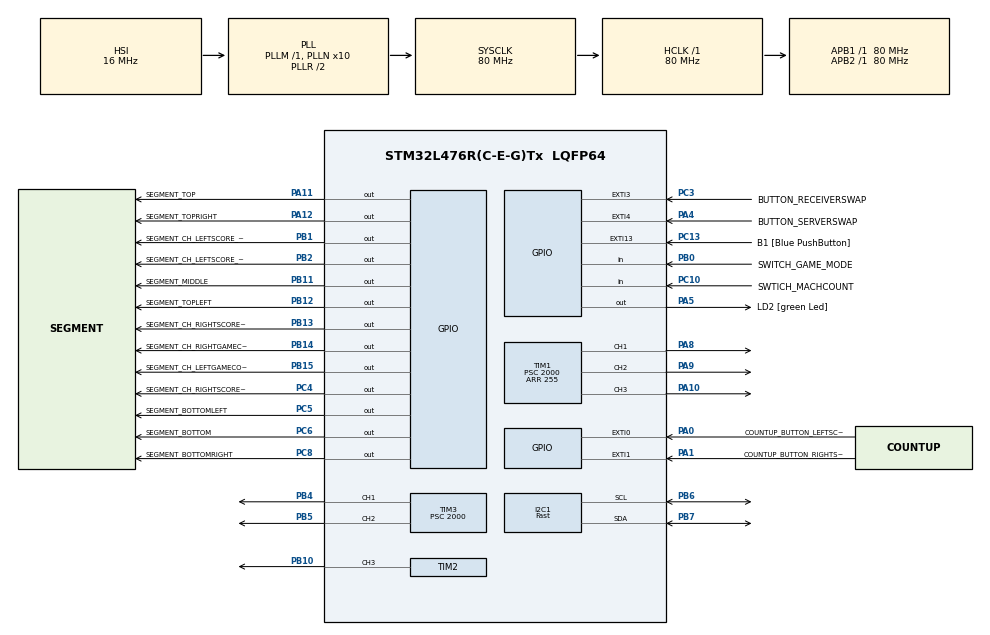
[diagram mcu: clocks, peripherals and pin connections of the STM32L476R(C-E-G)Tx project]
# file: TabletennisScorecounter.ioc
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I2C1.I2C_Speed_Mode=I2C_Fast
I2C1.Timing=0x00702991
Mcu.Family=STM32L4
Mcu.Name=STM32L476R(C-E-G)Tx
Mcu.Package=LQFP64
NVIC.EXTI0_IRQn=true\:0\:0\:false\:false\:true\:true
NVIC.EXTI15_10_IRQn=true\:0\:0\:false\:false\:true\:true
NVIC.EXTI1_IRQn=true\:0\:0\:false\:false\:true\:true
NVIC.EXTI3_IRQn=true\:0\:0\:false\:false\:true\:true
NVIC.EXTI4_IRQn=true\:0\:0\:false\:false\:true\:true
NVIC.PriorityGroup=NVIC_PRIORITYGROUP_4
NVIC.TIM2_IRQn=true\:0\:0\:false\:false\:true\:true
NVIC.TIM3_IRQn=true\:0\:0\:false\:false\:true\:true
NVIC.TIM4_IRQn=true\:0\:0\:false\:false\:true\:true
NVIC.TIM5_IRQn=true\:0\:0\:false\:false\:true\:true
PA0.GPIO_Label=COUNTUP_BUTTON_LEFTSCORE
PA0.GPIO_ModeDefaultEXTI=GPIO_MODE_IT_RISING
PA0.GPIO_PuPd=GPIO_NOPULL
PA0.Signal=GPXTI0
PA1.GPIO_Label=COUNTUP_BUTTON_RIGHTSCORE
PA1.GPIO_ModeDefaultEXTI=GPIO_MODE_IT_RISING
PA1.GPIO_PuPd=GPIO_NOPULL
PA1.Signal=GPXTI1
PA10.Signal=S_TIM1_CH3
PA11.GPIO_Label=SEGMENT_TOP
PA11.Signal=GPIO_Output
PA12.GPIO_Label=SEGMENT_TOPRIGHT
PA12.Signal=GPIO_Output
PA13\ (JTMS-SWDIO).GPIO_Label=TMS
PA13\ (JTMS-SWDIO).Signal=SYS_JTMS-SWDIO
PA14\ (JTCK-SWCLK).GPIO_Label=TCK
PA14\ (JTCK-SWCLK).Signal=SYS_JTCK-SWCLK
PA4.GPIO_Label=BUTTON_SERVERSWAP
PA4.GPIO_PuPd=GPIO_PULLUP
PA4.Signal=GPXTI4
PA5.GPIO_Label=LD2 [green Led]
PA5.GPIO_ModeDefaultOutputPP=GPIO_MODE_OUTPUT_PP
PA5.GPIO_PuPd=GPIO_NOPULL
PA5.GPIO_Speed=GPIO_SPEED_FREQ_LOW
PA5.Signal=GPIO_Output
PA8.Signal=S_TIM1_CH1
PA9.Signal=S_TIM1_CH2
PB0.GPIO_Label=SWITCH_GAME_MODE
PB0.GPIO_PuPd=GPIO_PULLUP
PB0.Signal=GPIO_Input
PB1.GPIO_Label=SEGMENT_CH_LEFTSCORE_UPPER
PB1.Signal=GPIO_Output
PB10.Signal=S_TIM2_CH3
PB11.GPIO_Label=SEGMENT_MIDDLE
PB11.Signal=GPIO_Output
PB12.GPIO_Label=SEGMENT_TOPLEFT
PB12.Signal=GPIO_Output
PB13.GPIO_Label=SEGMENT_CH_RIGHTSCORE_LOWER
PB13.Signal=GPIO_Output
PB14.GPIO_Label=SEGMENT_CH_RIGHTGAMECOUNT
PB14.Signal=GPIO_Output
PB15.GPIO_Label=SEGMENT_CH_LEFTGAMECOUNT
PB15.Signal=GPIO_Output
PB2.GPIO_Label=SEGMENT_CH_LEFTSCORE_LOWER
PB2.Signal=GPIO_Output
PB3\ (JTDO-TRACESWO).GPIO_Label=SWO
PB3\ (JTDO-TRACESWO).Signal=SYS_JTDO-SWO
PB4\ (NJTRST).Signal=S_TIM3_CH1
PB5.Signal=S_TIM3_CH2
PB6.Mode=I2C
PB6.Signal=I2C1_SCL
PB7.Mode=I2C
PB7.Signal=I2C1_SDA
PC10.GPIO_Label=SWTICH_MACHCOUNT
PC10.Signal=GPIO_Input
PC13.GPIO_Label=B1 [Blue PushButton]
PC13.GPIO_ModeDefaultEXTI=GPIO_MODE_IT_RISING
PC13.GPIO_PuPd=GPIO_PULLDOWN
PC13.Signal=GPXTI13
PC14-OSC32_IN\ (PC14).Signal=RCC_OSC32_IN
PC15-OSC32_OUT\ (PC15).Signal=RCC_OSC32_OUT
PC3.GPIO_Label=BUTTON_RECEIVERSWAP
PC3.GPIO_PuPd=GPIO_PULLUP
PC3.Signal=GPXTI3
PC4.GPIO_Label=SEGMENT_CH_RIGHTSCORE_UPPER
PC4.Signal=GPIO_Output
PC5.GPIO_Label=SEGMENT_BOTTOMLEFT
PC5.Signal=GPIO_Output
PC6.GPIO_Label=SEGMENT_BOTTOM
PC6.Signal=GPIO_Output
PC8.GPIO_Label=SEGMENT_BOTTOMRIGHT
PC8.Signal=GPIO_Output
PH0-OSC_IN\ (PH0).Signal=RCC_OSC_IN
PH1-OSC_OUT\ (PH1).Signal=RCC_OSC_OUT
ProjectManager.HeapSize=0x200
ProjectManager.StackSize=0x400
ProjectManager.TargetToolchain=Makefile
RCC.ADCFreq_Value=64000000
RCC.AHBFreq_Value=80000000
RCC.APB1Freq_Value=80000000
RCC.APB1TimFreq_Value=80000000
RCC.APB2Freq_Value=80000000
RCC.APB2TimFreq_Value=80000000
RCC.CortexFreq_Value=80000000
RCC.HCLKFreq_Value=80000000
RCC.HSE_VALUE=8000000
RCC.HSI_VALUE=16000000
RCC.LSE_VALUE=32768
RCC.MSI_VALUE=4000000
RCC.PLLN=10
RCC.PLLSourceVirtual=RCC_PLLSOURCE_HSI
RCC.PREFETCH_ENABLE=1
RCC.SYSCLKFreq_VALUE=80000000
RCC.SYSCLKSource=RCC_SYSCLKSOURCE_PLLCLK
RCC.USBFreq_Value=64000000
RCC.VCOOutputFreq_Value=160000000
SH.S_TIM1_CH1.0=TIM1_CH1,PWM Generation1 CH1
SH.S_TIM1_CH2.0=TIM1_CH2,PWM Generation2 CH2
SH.S_TIM1_CH3.0=TIM1_CH3,PWM Generation3 CH3
SH.S_TIM2_CH3.0=TIM2_CH3,PWM Generation3 CH3
SH.S_TIM3_CH1.0=TIM3_CH1,PWM Generation1 CH1
SH.S_TIM3_CH2.0=TIM3_CH2,PWM Generation2 CH2
TIM1.Channel-PWM\ Generation1\ CH1=TIM_CHANNEL_1
TIM1.Channel-PWM\ Generation2\ CH2=TIM_CHANNEL_2
TIM1.Channel-PWM\ Generation3\ CH3=TIM_CHANNEL_3
TIM1.ClockDivision=TIM_CLOCKDIVISION_DIV4
TIM1.Period=255
TIM1.Prescaler=2000
TIM1.Pulse-PWM\ Generation1\ CH1=0
TIM2.Channel-PWM\ Generation3\ CH3=TIM_CHANNEL_3
TIM2.ClockDivision=TIM_CLOCKDIVISION_DIV4
TIM2.Period=255
TIM2.Prescaler=2000
TIM3.Channel-PWM\ Generation1\ CH1=TIM_CHANNEL_1
TIM3.Channel-PWM\ Generation2\ CH2=TIM_CHANNEL_2
TIM3.ClockDivision=TIM_CLOCKDIVISION_DIV4
TIM3.Period=255
TIM3.Prescaler=2000
TIM4.ClockDivision=TIM_CLOCKDIVISION_DIV4
TIM4.Period=100
TIM4.Prescaler=2000
TIM5.ClockDivision=TIM_CLOCKDIVISION_DIV4
TIM5.Period=100
TIM5.Prescaler=2000
TIM6.Period=65535
TIM6.Prescaler=8000
VP_TIM1_VS_ClockSourceINT.Mode=Internal
VP_TIM2_VS_ClockSourceINT.Mode=Internal
VP_TIM3_VS_ClockSourceINT.Mode=Internal
VP_TIM4_VS_ClockSourceINT.Mode=Internal
VP_TIM5_VS_ClockSourceINT.Mode=Internal
VP_TIM6_VS_ClockSourceINT.Mode=Enable_Timer
board=NUCLEO-L476RG

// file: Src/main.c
/**
  ******************************************************************************
  * @file           : main.c
  * @brief          : Main program body
  ******************************************************************************
  ** This notice applies to any and all portions of this file
  * that are not between comment pairs USER CODE BEGIN and
  * USER CODE END. Other portions of this file, whether
  * inserted by the user or by software development tools
  * are owned by their respective copyright owners.
  *
  * COPYRIGHT(c) 2019 STMicroelectronics
  *
  * Redistribution and use in source and binary forms, with or without modification,
  * are permitted provided that the following conditions are met:
  *   1. Redistributions of source code must retain the above copyright notice,
  *      this list of conditions and the following disclaimer.
  *   2. Redistributions in binary form must reproduce the above copyright notice,
  *      this list of conditions and the following disclaimer in the documentation
  *      and/or other materials provided with the distribution.
  *   3. Neither the name of STMicroelectronics nor the names of its contributors
  *      may be used to endorse or promote products derived from this software
  *      without specific prior written permission.
  *
  * THIS SOFTWARE IS PROVIDED BY THE COPYRIGHT HOLDERS AND CONTRIBUTORS "AS IS"
  * AND ANY EXPRESS OR IMPLIED WARRANTIES, INCLUDING, BUT NOT LIMITED TO, THE
  * IMPLIED WARRANTIES OF MERCHANTABILITY AND FITNESS FOR A PARTICULAR PURPOSE ARE
  * DISCLAIMED. IN NO EVENT SHALL THE COPYRIGHT HOLDER OR CONTRIBUTORS BE LIABLE
  * FOR ANY DIRECT, INDIRECT, INCIDENTAL, SPECIAL, EXEMPLARY, OR CONSEQUENTIAL
  * DAMAGES (INCLUDING, BUT NOT LIMITED TO, PROCUREMENT OF SUBSTITUTE GOODS OR
  * SERVICES; LOSS OF USE, DATA, OR PROFITS; OR BUSINESS INTERRUPTION) HOWEVER
  * CAUSED AND ON ANY THEORY OF LIABILITY, WHETHER IN CONTRACT, STRICT LIABILITY,
  * OR TORT (INCLUDING NEGLIGENCE OR OTHERWISE) ARISING IN ANY WAY OUT OF THE USE
  * OF THIS SOFTWARE, EVEN IF ADVISED OF THE POSSIBILITY OF SUCH DAMAGE.
  *
  ******************************************************************************
  */
#include "main.h"
#include "stm32l4xx_hal.h"
#include "i2c.h"
#include "tim.h"
#include "gpio.h"

/* USER CODE BEGIN Includes */
#include "MainWrapper.hpp"
/* USER CODE END Includes */

/* USER CODE BEGIN PV */
/* Private variables ---------------------------------------------------------*/

/* USER CODE END PV */

void SystemClock_Config(void);

/* USER CODE BEGIN PFP */
/* Private function prototypes -----------------------------------------------*/

/* USER CODE END PFP */

int main(void)
{

  /* MCU Configuration----------------------------------------------------------*/

  /* Reset of all peripherals, Initializes the Flash interface and the Systick. */
  HAL_Init();

  /* Configure the system clock */
  SystemClock_Config();

  /* Initialize all configured peripherals */
  MX_GPIO_Init();
  MX_TIM2_Init();
  MX_TIM3_Init();
  MX_TIM4_Init();
  MX_TIM5_Init();
  MX_TIM1_Init();
  MX_TIM6_Init();
  MX_I2C1_Init();
  /* USER CODE BEGIN 2 */
  CWrappedMain();
  /* USER CODE END 2 */

  /* Infinite loop */
  while (1)
  {

  }

}

void SystemClock_Config(void)
{

  RCC_OscInitTypeDef RCC_OscInitStruct;
  RCC_ClkInitTypeDef RCC_ClkInitStruct;
  RCC_PeriphCLKInitTypeDef PeriphClkInit;

    /**Initializes the CPU, AHB and APB busses clocks
    */
  RCC_OscInitStruct.OscillatorType = RCC_OSCILLATORTYPE_HSI;
  RCC_OscInitStruct.HSIState = RCC_HSI_ON;
  RCC_OscInitStruct.HSICalibrationValue = 16;
  RCC_OscInitStruct.PLL.PLLState = RCC_PLL_ON;
  RCC_OscInitStruct.PLL.PLLSource = RCC_PLLSOURCE_HSI;
  RCC_OscInitStruct.PLL.PLLM = 1;
  RCC_OscInitStruct.PLL.PLLN = 10;
  RCC_OscInitStruct.PLL.PLLP = RCC_PLLP_DIV7;
  RCC_OscInitStruct.PLL.PLLQ = RCC_PLLQ_DIV2;
  RCC_OscInitStruct.PLL.PLLR = RCC_PLLR_DIV2;
  if (HAL_RCC_OscConfig(&RCC_OscInitStruct) != HAL_OK)
  {
    _Error_Handler(__FILE__, __LINE__);
  }

    /**Initializes the CPU, AHB and APB busses clocks
    */
  RCC_ClkInitStruct.ClockType = RCC_CLOCKTYPE_HCLK|RCC_CLOCKTYPE_SYSCLK
                              |RCC_CLOCKTYPE_PCLK1|RCC_CLOCKTYPE_PCLK2;
  RCC_ClkInitStruct.SYSCLKSource = RCC_SYSCLKSOURCE_PLLCLK;
  RCC_ClkInitStruct.AHBCLKDivider = RCC_SYSCLK_DIV1;
  RCC_ClkInitStruct.APB1CLKDivider = RCC_HCLK_DIV1;
  RCC_ClkInitStruct.APB2CLKDivider = RCC_HCLK_DIV1;

  if (HAL_RCC_ClockConfig(&RCC_ClkInitStruct, FLASH_LATENCY_4) != HAL_OK)
  {
    _Error_Handler(__FILE__, __LINE__);
  }

  PeriphClkInit.PeriphClockSelection = RCC_PERIPHCLK_I2C1;
  PeriphClkInit.I2c1ClockSelection = RCC_I2C1CLKSOURCE_PCLK1;
  if (HAL_RCCEx_PeriphCLKConfig(&PeriphClkInit) != HAL_OK)
  {
    _Error_Handler(__FILE__, __LINE__);
  }

    /**Configure the main internal regulator output voltage
    */
  if (HAL_PWREx_ControlVoltageScaling(PWR_REGULATOR_VOLTAGE_SCALE1) != HAL_OK)
  {
    _Error_Handler(__FILE__, __LINE__);
  }

    /**Configure the Systick interrupt time
    */
  HAL_SYSTICK_Config(HAL_RCC_GetHCLKFreq()/1000);

    /**Configure the Systick
    */
  HAL_SYSTICK_CLKSourceConfig(SYSTICK_CLKSOURCE_HCLK);

  /* SysTick_IRQn interrupt configuration */
  HAL_NVIC_SetPriority(SysTick_IRQn, 0, 0);
}

void _Error_Handler(char *file, int line)
{
  while(1)
  {
  }
}

/************************ (C) COPYRIGHT STMicroelectronics *****END OF FILE****/
